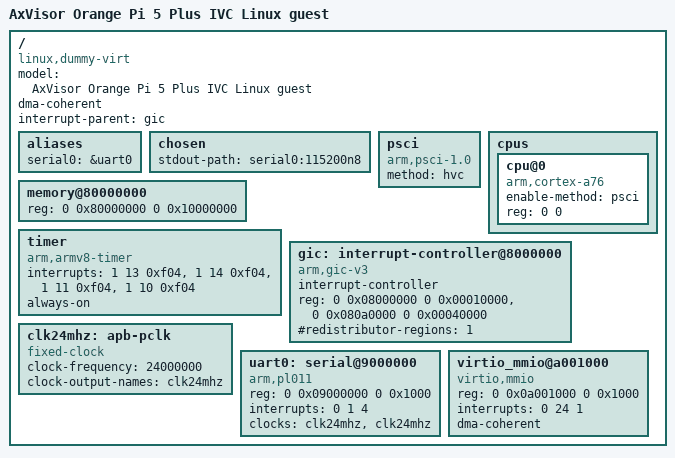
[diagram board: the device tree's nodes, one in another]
/dts-v1/;

/ {
	compatible = "linux,dummy-virt";
	model = "AxVisor Orange Pi 5 Plus IVC Linux guest";
	#address-cells = <2>;
	#size-cells = <2>;
	dma-coherent;
	interrupt-parent = <&gic>;

	aliases {
		serial0 = &uart0;
	};

	chosen {
		stdout-path = "serial0:115200n8";
	};

	psci {
		compatible = "arm,psci-1.0", "arm,psci-0.2";
		method = "hvc";
	};

	/* AxVisor replaces this topology with the selected RK3588 host CPUs. */
	cpus {
		#address-cells = <2>;
		#size-cells = <0>;

		cpu@0 {
			compatible = "arm,cortex-a76";
			device_type = "cpu";
			enable-method = "psci";
			reg = <0 0>;
		};
	};

	/* AxVisor rebuilds memory nodes from the VM memory configuration. */
	memory@80000000 {
		device_type = "memory";
		reg = <0 0x80000000 0 0x10000000>;
	};

	timer {
		compatible = "arm,armv8-timer";
		interrupts = <1 13 0xf04>,
			     <1 14 0xf04>,
			     <1 11 0xf04>,
			     <1 10 0xf04>;
		always-on;
	};

	gic: interrupt-controller@8000000 {
		compatible = "arm,gic-v3";
		#interrupt-cells = <3>;
		#address-cells = <2>;
		#size-cells = <2>;
		interrupt-controller;
		ranges;
		reg = <0 0x08000000 0 0x00010000>,
		      <0 0x080a0000 0 0x00040000>;
		#redistributor-regions = <1>;
	};

	clk24mhz: apb-pclk {
		compatible = "fixed-clock";
		#clock-cells = <0>;
		clock-frequency = <24000000>;
		clock-output-names = "clk24mhz";
	};

	uart0: serial@9000000 {
		compatible = "arm,pl011", "arm,primecell";
		reg = <0 0x09000000 0 0x1000>;
		interrupts = <0 1 4>;
		clocks = <&clk24mhz>, <&clk24mhz>;
		clock-names = "uartclk", "apb_pclk";
		status = "okay";
	};

	virtio_mmio@a001000 {
		compatible = "virtio,mmio";
		reg = <0 0x0a001000 0 0x1000>;
		interrupts = <0 24 1>;
		dma-coherent;
	};
};
